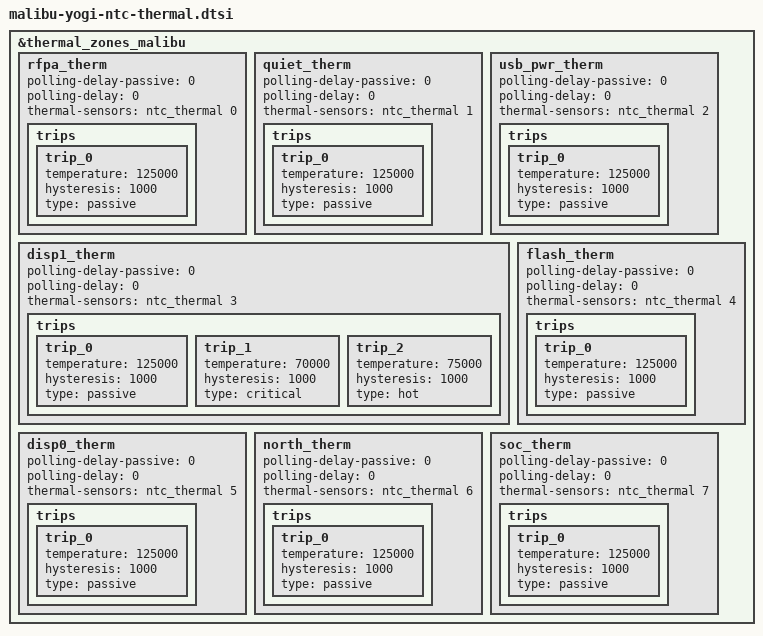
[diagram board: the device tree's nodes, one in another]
// SPDX-License-Identifier: GPL-2.0 OR BSD-3-Clause

&thermal_zones_malibu {
	/* NTC thermistors. */
	rfpa_therm {
		polling-delay-passive = <0>;
		polling-delay = <0>;
		thermal-sensors = <&ntc_thermal 0>;
		trips {
			trip_0 {
				temperature = <125000>;
				hysteresis = <1000>;
				type = "passive";
			};
		};
	};

	quiet_therm {
		polling-delay-passive = <0>;
		polling-delay = <0>;
		thermal-sensors = <&ntc_thermal 1>;
		trips {
			trip_0 {
				temperature = <125000>;
				hysteresis = <1000>;
				type = "passive";
			};
		};
	};

	usb_pwr_therm {
		polling-delay-passive = <0>;
		polling-delay = <0>;
		thermal-sensors = <&ntc_thermal 2>;
		trips {
			trip_0 {
				temperature = <125000>;
				hysteresis = <1000>;
				type = "passive";
			};
		};
	};

	disp1_therm {
		polling-delay-passive = <0>;
		polling-delay = <0>;
		thermal-sensors = <&ntc_thermal 3>;
		trips {
			trip_0 {
				temperature = <125000>;
				hysteresis = <1000>;
				type = "passive";
			};
			trip_1 {
				temperature = <70000>;
				hysteresis = <1000>;
				type = "critical";
			};
			trip_2 {
				temperature = <75000>;
				hysteresis = <1000>;
				type = "hot";
			};

		};
	};

	flash_therm {
		polling-delay-passive = <0>;
		polling-delay = <0>;
		thermal-sensors = <&ntc_thermal 4>;
		trips {
			trip_0 {
				temperature = <125000>;
				hysteresis = <1000>;
				type = "passive";
			};
		};
	};

	disp0_therm {
		polling-delay-passive = <0>;
		polling-delay = <0>;
		thermal-sensors = <&ntc_thermal 5>;
		trips {
			trip_0 {
				temperature = <125000>;
				hysteresis = <1000>;
				type = "passive";
			};
		};
	};

	north_therm {
		polling-delay-passive = <0>;
		polling-delay = <0>;
		thermal-sensors = <&ntc_thermal 6>;
		trips {
			trip_0 {
				temperature = <125000>;
				hysteresis = <1000>;
				type = "passive";
			};
		};
	};

	soc_therm {
		polling-delay-passive = <0>;
		polling-delay = <0>;
		thermal-sensors = <&ntc_thermal 7>;
		trips {
			trip_0 {
				temperature = <125000>;
				hysteresis = <1000>;
				type = "passive";
			};
		};
	};
};
